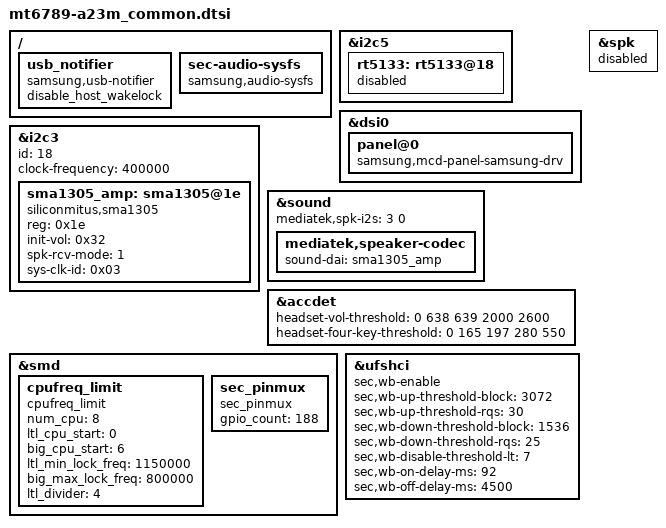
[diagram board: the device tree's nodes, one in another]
/* Generated by Samsung for MTK vendor board
 * If these files should be changed, then please make a sync with MTK
*/

/* Add Samsung configuration over here */
/ {
	fragment@model {
		target-path = "/";
		__overlay__ {
			usb_notifier {
				compatible = "samsung,usb-notifier";
				disable_host_wakelock;
			};

			sec-audio-sysfs {
				compatible = "samsung,audio-sysfs";
				status = "okay";
				/* audio,no-earjack; */
				/* audio,num-amp = <1>; */
			};
		};
	};
};

&i2c5 {
	rt5133: rt5133@18 {
		status = "disabled";
	};
};

&dsi0 {
	panel@0 {
		compatible = "samsung,mcd-panel-samsung-drv";
	};
};

&spk {
	status = "disabled";
};

&i2c3 {
	status = "okay";
	id = <18>;
	clock-frequency = <400000>;
	#address-cells = <1>;
	#size-cells = <0>;

	sma1305_amp: sma1305@1e {
		compatible = "siliconmitus,sma1305";
		#sound-dai-cells = <0>;

		reg = <0x1e>;
		init-vol = <0x32>;
		/* SPK_4.0W_MODE   : 0x00,
		 * SPK_6.0W_MODE   : 0x01,
		 * RCV_0.1W_MODE   : 0x02,
		 * RCV_0.5W_MODE   : 0x03,
		 */
		spk-rcv-mode = <1>;
		/* EXTERNAL_CLOCK_19_2   : 0x00,
		 * EXTERNAL_CLOCK_24_576 : 0x01,
		 * PLL_CLKIN_MCLK        : 0x02,
		 * PLL_CLKIN_BCLK        : 0x03
		 */
		sys-clk-id = <0x03>;
		status = "okay";
	};
};

&sound {
	mediatek,spk-i2s = <3 0>;
	mediatek,speaker-codec {
		sound-dai = <&sma1305_amp>;
	};
};

&accdet {
	/* min_3pole--max_3pole--min_4pole--max_4pole--vol_bias */
	headset-vol-threshold = <0 638 639 2000 2600>;
	/* 0--MD_MAX--VOICE_MAX--UP_MAX--DW_MAX */
	headset-four-key-threshold = <0 165 197 280 550>;
};

&smd {
	cpufreq_limit {
		status = "okay";
		compatible = "cpufreq_limit";

		num_cpu = <8>;
		ltl_cpu_start = <0>;
		big_cpu_start = <6>;
		ltl_min_lock_freq = <1150000>;
		big_max_lock_freq = <800000>;
		ltl_divider = <4>;
	};

	sec_pinmux {
		status = "okay";
		compatible = "sec_pinmux";

		gpio_count = <188>;
	};
};

&ufshci {
	/* CONFIG_SEC_UFS_WB_FEATURE */
	/* default WB configuration */
	sec,wb-enable;

	/* up threshold for WB on */
	sec,wb-up-threshold-block = <3072>;
	sec,wb-up-threshold-rqs = <30>;

	/* down threshold for WB off */
	sec,wb-down-threshold-block = <1536>;
	sec,wb-down-threshold-rqs = <25>;

	sec,wb-disable-threshold-lt = <7>;

	sec,wb-on-delay-ms = <92>;
	sec,wb-off-delay-ms = <4500>;
};
